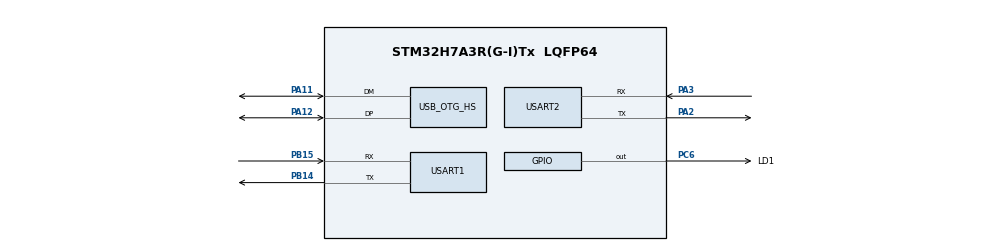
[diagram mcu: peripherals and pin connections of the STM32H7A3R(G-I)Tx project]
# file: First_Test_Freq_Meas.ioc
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CORTEX_M7.default_mode_Activation=1
Mcu.Family=STM32H7
Mcu.Name=STM32H7A3R(G-I)Tx
Mcu.Package=LQFP64
NVIC.CRS_IRQn=true\:0\:0\:false\:false\:true\:true\:true\:true
NVIC.OTG_HS_IRQn=true\:0\:0\:false\:false\:true\:false\:true\:true
NVIC.PriorityGroup=NVIC_PRIORITYGROUP_4
NVIC.RCC_IRQn=true\:0\:0\:false\:false\:true\:true\:false\:true
PA11.Mode=Device_Only_FS
PA11.Signal=USB_OTG_HS_DM
PA12.Mode=Device_Only_FS
PA12.Signal=USB_OTG_HS_DP
PA2.Mode=Asynchronous
PA2.Signal=USART2_TX
PA3.Mode=Asynchronous
PA3.Signal=USART2_RX
PB14.Mode=Asynchronous
PB14.Signal=USART1_TX
PB15.Mode=Asynchronous
PB15.Signal=USART1_RX
PC6.GPIO_Label=LD1
PC6.GPIO_PuPd=GPIO_NOPULL
PC6.PinState=GPIO_PIN_RESET
PC6.Signal=GPIO_Output
PH0-OSC_IN.Mode=HSE-External-Clock-Source
PH0-OSC_IN.Signal=RCC_OSC_IN
ProjectManager.HeapSize=0x200
ProjectManager.StackSize=0x400
ProjectManager.TargetToolchain=STM32CubeIDE
RCC.ADCFreq_Value=48375000
RCC.APB1Freq_Value=24000000
RCC.APB2Freq_Value=24000000
RCC.APB3Freq_Value=24000000
RCC.APB4Freq_Value=24000000
RCC.CortexFreq_Value=24000000
RCC.DIVM1=2
RCC.DIVN1=11
RCC.HCLKFreq_Value=24000000
RCC.PLLSourceVirtual=RCC_PLLSOURCE_HSE
RCC.SYSCLKFreq_VALUE=24000000
RCC.SYSCLKSource=RCC_SYSCLKSOURCE_HSE
RCC.USBCLockSelection=RCC_USBCLKSOURCE_HSI48
RCC.USBFreq_Value=48000000
USART1.VirtualMode-Asynchronous=VM_ASYNC
USART1.VirtualMode-Synchronous=VM_SYNC
USART2.VirtualMode-Asynchronous=VM_ASYNC
USB_DEVICE.CLASS_NAME_HS=CDC
USB_DEVICE.VirtualMode=Cdc
USB_DEVICE.VirtualModeHS=Cdc_HS
USB_OTG_HS.VirtualMode=Device_Only_FS
VP_MEMORYMAP_VS_MEMORYMAP.Mode=CurAppReg
VP_RCC_USB.Mode=USB_HS
VP_USB_DEVICE_VS_USB_DEVICE_CDC_HS.Mode=CDC_HS
board=custom

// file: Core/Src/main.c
/* USER CODE BEGIN Header */
/**
  ******************************************************************************
  * @file           : main.c
  * @brief          : Main program body
  ******************************************************************************
  * @attention
  *
  * Copyright (c) 2024 STMicroelectronics.
  * All rights reserved.
  *
  * This software is licensed under terms that can be found in the LICENSE file
  * in the root directory of this software component.
  * If no LICENSE file comes with this software, it is provided AS-IS.
  *
  ******************************************************************************
  */
/* USER CODE END Header */
#include "main.h"
#include "usb_device.h"

UART_HandleTypeDef huart1;
UART_HandleTypeDef huart2;

void SystemClock_Config(void);
static void MPU_Config(void);
static void MX_GPIO_Init(void);
static void MX_USART1_UART_Init(void);
static void MX_USART2_UART_Init(void);

int main(void)
{

  /* MPU Configuration--------------------------------------------------------*/
  MPU_Config();

  /* MCU Configuration--------------------------------------------------------*/

  /* Reset of all peripherals, Initializes the Flash interface and the Systick. */
  HAL_Init();

  /* Configure the system clock */
  SystemClock_Config();

  /* Initialize all configured peripherals */
  MX_GPIO_Init();
  MX_USB_DEVICE_Init();
  MX_USART1_UART_Init();
  MX_USART2_UART_Init();
  /* USER CODE BEGIN 2 */
  char txBuf[] = "Hello World \n \r";
  //uint8_t count = 1;
  /* USER CODE END 2 */

  /* Infinite loop */
  while (1)
  {

    /* USER CODE BEGIN 3 */
	  HAL_GPIO_TogglePin(LD1_GPIO_Port, LD1_Pin);
	  HAL_UART_Transmit(&huart2, (uint8_t *)txBuf, sizeof(txBuf) - 1, HAL_MAX_DELAY);
	  HAL_UART_Transmit(&huart1, (uint8_t *)txBuf, sizeof(txBuf) - 1, HAL_MAX_DELAY);
	  HAL_Delay(1000);

  }
  /* USER CODE END 3 */
}

void SystemClock_Config(void)
{
  RCC_OscInitTypeDef RCC_OscInitStruct = {0};
  RCC_ClkInitTypeDef RCC_ClkInitStruct = {0};
  RCC_CRSInitTypeDef RCC_CRSInitStruct = {0};

  /*AXI clock gating */
  RCC->CKGAENR = 0xFFFFFFFF;

  /** Supply configuration update enable
  */
  HAL_PWREx_ConfigSupply(PWR_LDO_SUPPLY);

  /** Configure the main internal regulator output voltage
  */
  __HAL_PWR_VOLTAGESCALING_CONFIG(PWR_REGULATOR_VOLTAGE_SCALE3);

  while(!__HAL_PWR_GET_FLAG(PWR_FLAG_VOSRDY)) {}

  /** Initializes the RCC Oscillators according to the specified parameters
  * in the RCC_OscInitTypeDef structure.
  */
  RCC_OscInitStruct.OscillatorType = RCC_OSCILLATORTYPE_HSI48|RCC_OSCILLATORTYPE_HSE;
  RCC_OscInitStruct.HSEState = RCC_HSE_BYPASS;
  RCC_OscInitStruct.HSI48State = RCC_HSI48_ON;
  RCC_OscInitStruct.PLL.PLLState = RCC_PLL_NONE;
  if (HAL_RCC_OscConfig(&RCC_OscInitStruct) != HAL_OK)
  {
    Error_Handler();
  }

  /** Initializes the CPU, AHB and APB buses clocks
  */
  RCC_ClkInitStruct.ClockType = RCC_CLOCKTYPE_HCLK|RCC_CLOCKTYPE_SYSCLK
                              |RCC_CLOCKTYPE_PCLK1|RCC_CLOCKTYPE_PCLK2
                              |RCC_CLOCKTYPE_D3PCLK1|RCC_CLOCKTYPE_D1PCLK1;
  RCC_ClkInitStruct.SYSCLKSource = RCC_SYSCLKSOURCE_HSE;
  RCC_ClkInitStruct.SYSCLKDivider = RCC_SYSCLK_DIV1;
  RCC_ClkInitStruct.AHBCLKDivider = RCC_HCLK_DIV1;
  RCC_ClkInitStruct.APB3CLKDivider = RCC_APB3_DIV1;
  RCC_ClkInitStruct.APB1CLKDivider = RCC_APB1_DIV1;
  RCC_ClkInitStruct.APB2CLKDivider = RCC_APB2_DIV1;
  RCC_ClkInitStruct.APB4CLKDivider = RCC_APB4_DIV1;

  if (HAL_RCC_ClockConfig(&RCC_ClkInitStruct, FLASH_LATENCY_1) != HAL_OK)
  {
    Error_Handler();
  }

  /** Enable the SYSCFG APB clock
  */
  __HAL_RCC_CRS_CLK_ENABLE();

  /** Configures CRS
  */
  RCC_CRSInitStruct.Prescaler = RCC_CRS_SYNC_DIV1;
  RCC_CRSInitStruct.Source = RCC_CRS_SYNC_SOURCE_USB2;
  RCC_CRSInitStruct.Polarity = RCC_CRS_SYNC_POLARITY_RISING;
  RCC_CRSInitStruct.ReloadValue = __HAL_RCC_CRS_RELOADVALUE_CALCULATE(48000000,1000);
  RCC_CRSInitStruct.ErrorLimitValue = 34;
  RCC_CRSInitStruct.HSI48CalibrationValue = 32;

  HAL_RCCEx_CRSConfig(&RCC_CRSInitStruct);
}

static void MX_USART1_UART_Init(void)
{

  huart1.Instance = USART1;
  huart1.Init.BaudRate = 115200;
  huart1.Init.WordLength = UART_WORDLENGTH_8B;
  huart1.Init.StopBits = UART_STOPBITS_1;
  huart1.Init.Parity = UART_PARITY_NONE;
  huart1.Init.Mode = UART_MODE_TX_RX;
  huart1.Init.HwFlowCtl = UART_HWCONTROL_NONE;
  huart1.Init.OverSampling = UART_OVERSAMPLING_16;
  huart1.Init.OneBitSampling = UART_ONE_BIT_SAMPLE_DISABLE;
  huart1.Init.ClockPrescaler = UART_PRESCALER_DIV1;
  huart1.AdvancedInit.AdvFeatureInit = UART_ADVFEATURE_NO_INIT;
  if (HAL_UART_Init(&huart1) != HAL_OK)
  {
    Error_Handler();
  }
  if (HAL_UARTEx_SetTxFifoThreshold(&huart1, UART_TXFIFO_THRESHOLD_1_8) != HAL_OK)
  {
    Error_Handler();
  }
  if (HAL_UARTEx_SetRxFifoThreshold(&huart1, UART_RXFIFO_THRESHOLD_1_8) != HAL_OK)
  {
    Error_Handler();
  }
  if (HAL_UARTEx_DisableFifoMode(&huart1) != HAL_OK)
  {
    Error_Handler();
  }

}

static void MX_USART2_UART_Init(void)
{

  huart2.Instance = USART2;
  huart2.Init.BaudRate = 115200;
  huart2.Init.WordLength = UART_WORDLENGTH_8B;
  huart2.Init.StopBits = UART_STOPBITS_1;
  huart2.Init.Parity = UART_PARITY_NONE;
  huart2.Init.Mode = UART_MODE_TX_RX;
  huart2.Init.HwFlowCtl = UART_HWCONTROL_NONE;
  huart2.Init.OverSampling = UART_OVERSAMPLING_16;
  huart2.Init.OneBitSampling = UART_ONE_BIT_SAMPLE_DISABLE;
  huart2.Init.ClockPrescaler = UART_PRESCALER_DIV1;
  huart2.AdvancedInit.AdvFeatureInit = UART_ADVFEATURE_NO_INIT;
  if (HAL_UART_Init(&huart2) != HAL_OK)
  {
    Error_Handler();
  }
  if (HAL_UARTEx_SetTxFifoThreshold(&huart2, UART_TXFIFO_THRESHOLD_1_8) != HAL_OK)
  {
    Error_Handler();
  }
  if (HAL_UARTEx_SetRxFifoThreshold(&huart2, UART_RXFIFO_THRESHOLD_1_8) != HAL_OK)
  {
    Error_Handler();
  }
  if (HAL_UARTEx_DisableFifoMode(&huart2) != HAL_OK)
  {
    Error_Handler();
  }

}

static void MX_GPIO_Init(void)
{
  GPIO_InitTypeDef GPIO_InitStruct = {0};

  /* GPIO Ports Clock Enable */
  __HAL_RCC_GPIOH_CLK_ENABLE();
  __HAL_RCC_GPIOA_CLK_ENABLE();
  __HAL_RCC_GPIOB_CLK_ENABLE();
  __HAL_RCC_GPIOC_CLK_ENABLE();

  /*Configure GPIO pin Output Level */
  HAL_GPIO_WritePin(LD1_GPIO_Port, LD1_Pin, GPIO_PIN_RESET);

  /*Configure GPIO pin : LD1_Pin */
  GPIO_InitStruct.Pin = LD1_Pin;
  GPIO_InitStruct.Mode = GPIO_MODE_OUTPUT_PP;
  GPIO_InitStruct.Pull = GPIO_NOPULL;
  GPIO_InitStruct.Speed = GPIO_SPEED_FREQ_LOW;
  HAL_GPIO_Init(LD1_GPIO_Port, &GPIO_InitStruct);

}

 /* MPU Configuration */

void MPU_Config(void)
{
  MPU_Region_InitTypeDef MPU_InitStruct = {0};

  /* Disables the MPU */
  HAL_MPU_Disable();

  /** Initializes and configures the Region and the memory to be protected
  */
  MPU_InitStruct.Enable = MPU_REGION_ENABLE;
  MPU_InitStruct.Number = MPU_REGION_NUMBER0;
  MPU_InitStruct.BaseAddress = 0x0;
  MPU_InitStruct.Size = MPU_REGION_SIZE_4GB;
  MPU_InitStruct.SubRegionDisable = 0x87;
  MPU_InitStruct.TypeExtField = MPU_TEX_LEVEL0;
  MPU_InitStruct.AccessPermission = MPU_REGION_NO_ACCESS;
  MPU_InitStruct.DisableExec = MPU_INSTRUCTION_ACCESS_DISABLE;
  MPU_InitStruct.IsShareable = MPU_ACCESS_SHAREABLE;
  MPU_InitStruct.IsCacheable = MPU_ACCESS_NOT_CACHEABLE;
  MPU_InitStruct.IsBufferable = MPU_ACCESS_NOT_BUFFERABLE;

  HAL_MPU_ConfigRegion(&MPU_InitStruct);
  /* Enables the MPU */
  HAL_MPU_Enable(MPU_PRIVILEGED_DEFAULT);

}

void Error_Handler(void)
{
  __disable_irq();
  while (1)
  {
  }
}
